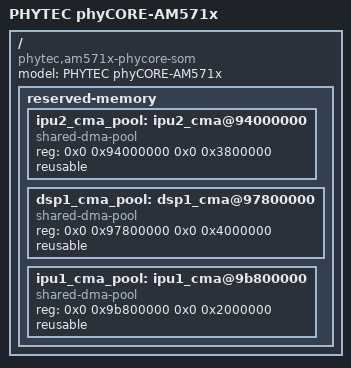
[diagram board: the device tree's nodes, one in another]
/*
 * Copyright (C) 2015 PHYTEC America, LLC. - www.phytec.com
 *
 * This program is free software; you can redistribute it and/or modify
 * it under the terms of the GNU General Public License version 2 as
 * published by the Free Software Foundation.
 */

#include "dra72x.dtsi"
#include <dt-bindings/gpio/gpio.h>
#include <dt-bindings/interrupt-controller/irq.h>
#include "am57xx-phycore-common.dtsi"

/ {
	model = "PHYTEC phyCORE-AM571x";
	compatible = "phytec,am571x-phycore-som", "ti,am5716", "ti,dra722", "ti,dra72", "ti,dra7";

	reserved-memory {
		#address-cells = <2>;
		#size-cells = <2>;
		ranges;

		ipu2_cma_pool: ipu2_cma@94000000 {
			compatible = "shared-dma-pool";
			reg = <0x0 0x94000000 0x0 0x3800000>;
			reusable;
			status = "okay";
		};

		dsp1_cma_pool: dsp1_cma@97800000 {
			compatible = "shared-dma-pool";
			reg = <0x0 0x97800000 0x0 0x4000000>;
			reusable;
			status = "okay";
		};

		ipu1_cma_pool: ipu1_cma@9b800000 {
			compatible = "shared-dma-pool";
			reg = <0x0 0x9b800000 0x0 0x2000000>;
			reusable;
			status = "okay";
		};
	};
};
